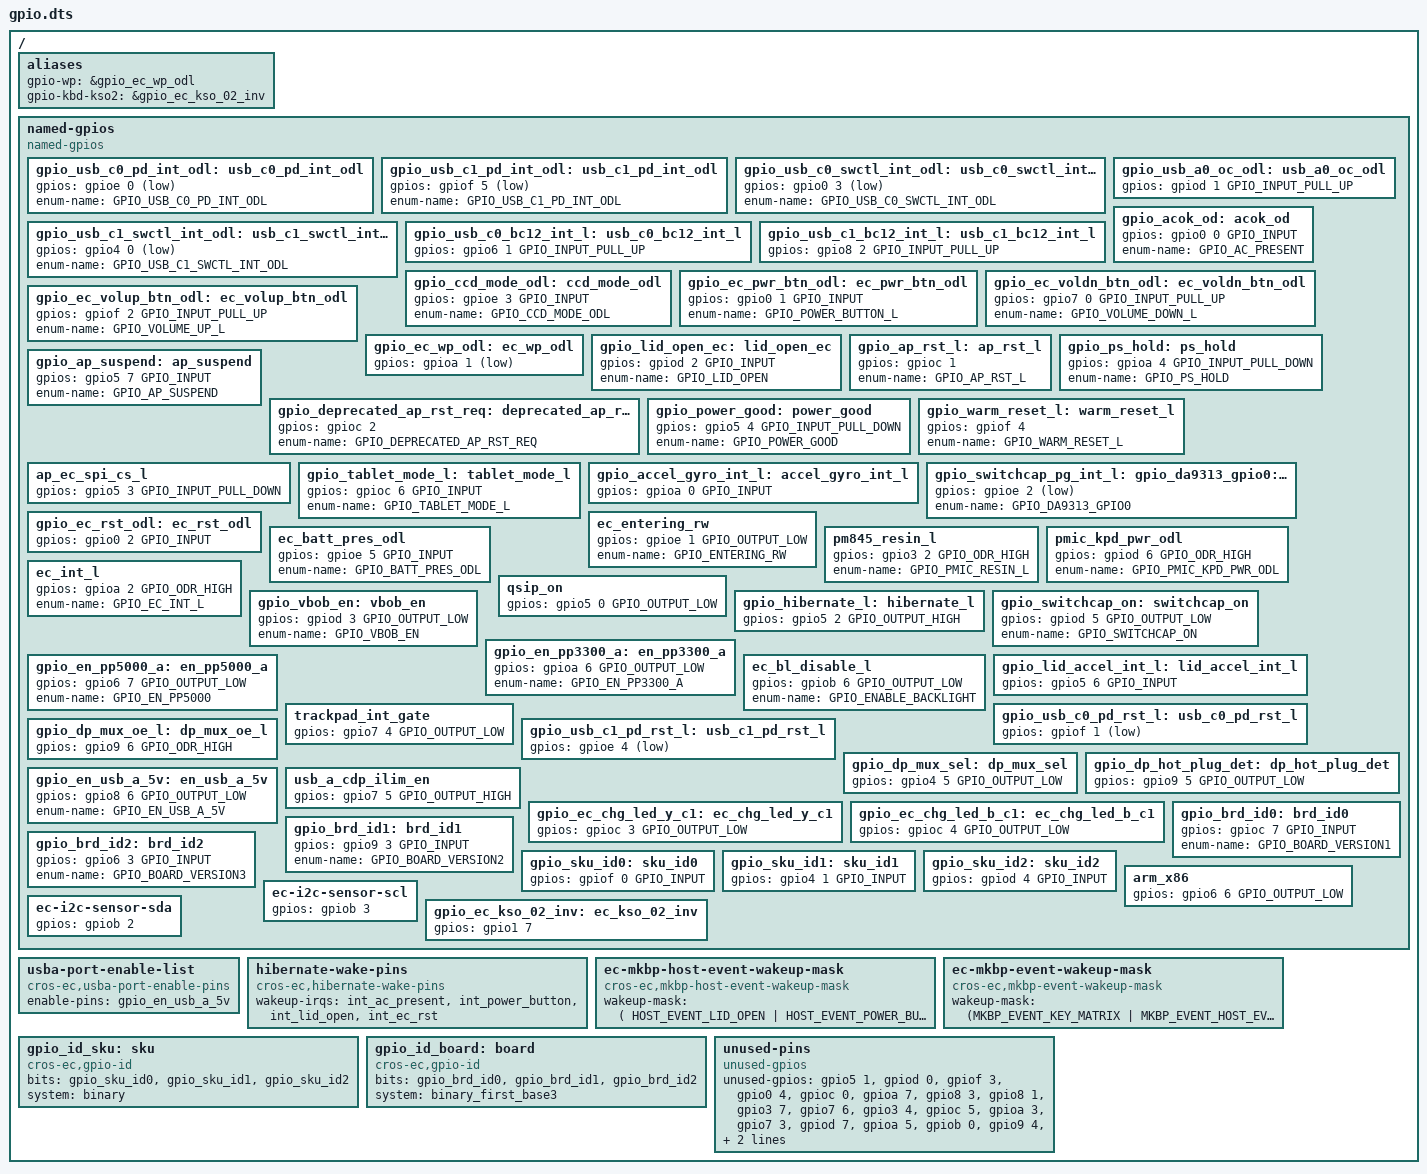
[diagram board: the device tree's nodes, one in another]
/* Copyright 2021 The ChromiumOS Authors
 * Use of this source code is governed by a BSD-style license that can be
 * found in the LICENSE file.
 */

#include <dt-bindings/wake_mask_event_defines.h>

/ {
	aliases {
		gpio-wp = &gpio_ec_wp_odl;
		gpio-kbd-kso2 = &gpio_ec_kso_02_inv;
	};

	named-gpios {
		compatible = "named-gpios";

		gpio_usb_c0_pd_int_odl: usb_c0_pd_int_odl {
			gpios = <&gpioe 0 (GPIO_INPUT | GPIO_ACTIVE_LOW)>;
			enum-name = "GPIO_USB_C0_PD_INT_ODL";
		};
		gpio_usb_c1_pd_int_odl: usb_c1_pd_int_odl {
			gpios = <&gpiof 5 (GPIO_INPUT | GPIO_ACTIVE_LOW)>;
			enum-name = "GPIO_USB_C1_PD_INT_ODL";
		};
		gpio_usb_c0_swctl_int_odl: usb_c0_swctl_int_odl {
			gpios = <&gpio0 3 (GPIO_INPUT | GPIO_ACTIVE_LOW)>;
			enum-name = "GPIO_USB_C0_SWCTL_INT_ODL";
		};
		gpio_usb_c1_swctl_int_odl: usb_c1_swctl_int_odl {
			gpios = <&gpio4 0 (GPIO_INPUT | GPIO_ACTIVE_LOW)>;
			enum-name = "GPIO_USB_C1_SWCTL_INT_ODL";
		};
		gpio_usb_c0_bc12_int_l: usb_c0_bc12_int_l {
			gpios = <&gpio6 1 GPIO_INPUT_PULL_UP>;
		};
		gpio_usb_c1_bc12_int_l: usb_c1_bc12_int_l {
			gpios = <&gpio8 2 GPIO_INPUT_PULL_UP>;
		};
		gpio_usb_a0_oc_odl: usb_a0_oc_odl {
			gpios = <&gpiod 1 GPIO_INPUT_PULL_UP>;
		};
		gpio_acok_od: acok_od {
			gpios = <&gpio0 0 GPIO_INPUT>;
			enum-name = "GPIO_AC_PRESENT";
		};
		gpio_ccd_mode_odl: ccd_mode_odl {
			gpios = <&gpioe 3 GPIO_INPUT>;
			enum-name = "GPIO_CCD_MODE_ODL";
		};
		gpio_ec_pwr_btn_odl: ec_pwr_btn_odl {
			gpios = <&gpio0 1 GPIO_INPUT>;
			enum-name = "GPIO_POWER_BUTTON_L";
		};
		gpio_ec_voldn_btn_odl: ec_voldn_btn_odl {
			gpios = <&gpio7 0 GPIO_INPUT_PULL_UP>;
			enum-name = "GPIO_VOLUME_DOWN_L";
		};
		gpio_ec_volup_btn_odl: ec_volup_btn_odl {
			gpios = <&gpiof 2 GPIO_INPUT_PULL_UP>;
			enum-name = "GPIO_VOLUME_UP_L";
		};
		gpio_ec_wp_odl: ec_wp_odl {
			gpios = <&gpioa 1 (GPIO_INPUT | GPIO_ACTIVE_LOW)>;
		};
		gpio_lid_open_ec: lid_open_ec {
			gpios = <&gpiod 2 GPIO_INPUT>;
			enum-name = "GPIO_LID_OPEN";
		};
		gpio_ap_rst_l: ap_rst_l {
			gpios = <&gpioc 1 (GPIO_INPUT | GPIO_VOLTAGE_1P8)>;
			enum-name = "GPIO_AP_RST_L";
		};
		gpio_ps_hold: ps_hold {
			gpios = <&gpioa 4 GPIO_INPUT_PULL_DOWN>;
			enum-name = "GPIO_PS_HOLD";
		};
		gpio_ap_suspend: ap_suspend {
			gpios = <&gpio5 7 GPIO_INPUT>;
			enum-name = "GPIO_AP_SUSPEND";
		};
		gpio_deprecated_ap_rst_req: deprecated_ap_rst_req {
			gpios = <&gpioc 2 (GPIO_INPUT_PULL_DOWN | GPIO_VOLTAGE_1P8)>;
			enum-name = "GPIO_DEPRECATED_AP_RST_REQ";
		};
		gpio_power_good: power_good {
			gpios = <&gpio5 4 GPIO_INPUT_PULL_DOWN>;
			enum-name = "GPIO_POWER_GOOD";
		};
		gpio_warm_reset_l: warm_reset_l {
			gpios = <&gpiof 4 (GPIO_INPUT | GPIO_VOLTAGE_1P8)>;
			enum-name = "GPIO_WARM_RESET_L";
		};
		ap_ec_spi_cs_l {
			gpios = <&gpio5 3 GPIO_INPUT_PULL_DOWN>;
		};
		gpio_tablet_mode_l: tablet_mode_l {
			gpios = <&gpioc 6 GPIO_INPUT>;
			enum-name = "GPIO_TABLET_MODE_L";
		};
		gpio_accel_gyro_int_l: accel_gyro_int_l {
			gpios = <&gpioa 0 GPIO_INPUT>;
		};
		/*
		 * Note, this signal is active low when used as the ln9310
		 * interrupt input, and active high when used as the da9313
		 * power good input.  The board code clears the active low
		 * flag when da9313 is detected.
		 */
		gpio_switchcap_pg_int_l: gpio_da9313_gpio0: da9313_gpio0 {
			gpios = <&gpioe 2 (GPIO_INPUT | GPIO_ACTIVE_LOW)>;
			enum-name = "GPIO_DA9313_GPIO0";
		};
		gpio_ec_rst_odl: ec_rst_odl {
			gpios = <&gpio0 2 GPIO_INPUT>;
		};
		ec_entering_rw {
			gpios = <&gpioe 1 GPIO_OUTPUT_LOW>;
			enum-name = "GPIO_ENTERING_RW";
		};
		ec_batt_pres_odl {
			gpios = <&gpioe 5 GPIO_INPUT>;
			enum-name = "GPIO_BATT_PRES_ODL";
		};
		pm845_resin_l {
			gpios = <&gpio3 2 GPIO_ODR_HIGH>;
			enum-name = "GPIO_PMIC_RESIN_L";
		};
		pmic_kpd_pwr_odl {
			gpios = <&gpiod 6 GPIO_ODR_HIGH>;
			enum-name = "GPIO_PMIC_KPD_PWR_ODL";
		};
		ec_int_l {
			gpios = <&gpioa 2 GPIO_ODR_HIGH>;
			enum-name = "GPIO_EC_INT_L";
		};
		qsip_on {
			gpios = <&gpio5 0 GPIO_OUTPUT_LOW>;
		};
		gpio_hibernate_l: hibernate_l {
			gpios = <&gpio5 2 GPIO_OUTPUT_HIGH>;
		};
		gpio_switchcap_on: switchcap_on {
			gpios = <&gpiod 5 GPIO_OUTPUT_LOW>;
			enum-name = "GPIO_SWITCHCAP_ON";
		};
		gpio_vbob_en: vbob_en {
			gpios = <&gpiod 3 GPIO_OUTPUT_LOW>;
			enum-name = "GPIO_VBOB_EN";
		};
		gpio_en_pp3300_a: en_pp3300_a {
			gpios = <&gpioa 6 GPIO_OUTPUT_LOW>;
			enum-name = "GPIO_EN_PP3300_A";
		};
		gpio_en_pp5000_a: en_pp5000_a {
			gpios = <&gpio6 7 GPIO_OUTPUT_LOW>;
			enum-name = "GPIO_EN_PP5000";
		};
		ec_bl_disable_l {
			gpios = <&gpiob 6 GPIO_OUTPUT_LOW>;
			enum-name = "GPIO_ENABLE_BACKLIGHT";
		};
		gpio_lid_accel_int_l: lid_accel_int_l {
			gpios = <&gpio5 6 GPIO_INPUT>;
		};
		trackpad_int_gate {
			gpios = <&gpio7 4 GPIO_OUTPUT_LOW>;
		};
		gpio_usb_c0_pd_rst_l: usb_c0_pd_rst_l {
			gpios = <&gpiof 1 (GPIO_ODR_HIGH | GPIO_ACTIVE_LOW)>;
		};
		gpio_usb_c1_pd_rst_l: usb_c1_pd_rst_l {
			gpios = <&gpioe 4 (GPIO_ODR_HIGH | GPIO_ACTIVE_LOW)>;
		};
		gpio_dp_mux_oe_l: dp_mux_oe_l {
			gpios = <&gpio9 6 GPIO_ODR_HIGH>;
		};
		gpio_dp_mux_sel: dp_mux_sel {
			gpios = <&gpio4 5 GPIO_OUTPUT_LOW>;
		};
		gpio_dp_hot_plug_det: dp_hot_plug_det {
			gpios = <&gpio9 5 GPIO_OUTPUT_LOW>;
		};
		gpio_en_usb_a_5v: en_usb_a_5v {
			gpios = <&gpio8 6 GPIO_OUTPUT_LOW>;
			enum-name = "GPIO_EN_USB_A_5V";
		};
		usb_a_cdp_ilim_en {
			gpios = <&gpio7 5 GPIO_OUTPUT_HIGH>;
		};
		gpio_ec_chg_led_y_c1: ec_chg_led_y_c1 {
			gpios = <&gpioc 3 GPIO_OUTPUT_LOW>;
		};
		gpio_ec_chg_led_b_c1: ec_chg_led_b_c1 {
			gpios = <&gpioc 4 GPIO_OUTPUT_LOW>;
		};
		gpio_brd_id0: brd_id0 {
			gpios = <&gpioc 7 GPIO_INPUT>;
			enum-name = "GPIO_BOARD_VERSION1";
		};
		gpio_brd_id1: brd_id1 {
			gpios = <&gpio9 3 GPIO_INPUT>;
			enum-name = "GPIO_BOARD_VERSION2";
		};
		gpio_brd_id2: brd_id2 {
			gpios = <&gpio6 3 GPIO_INPUT>;
			enum-name = "GPIO_BOARD_VERSION3";
		};
		gpio_sku_id0: sku_id0 {
			gpios = <&gpiof 0 GPIO_INPUT>;
		};
		gpio_sku_id1: sku_id1 {
			gpios = <&gpio4 1 GPIO_INPUT>;
		};
		gpio_sku_id2: sku_id2 {
			gpios = <&gpiod 4 GPIO_INPUT>;
		};
		arm_x86 {
			gpios = <&gpio6 6 GPIO_OUTPUT_LOW>;
		};
		ec-i2c-sensor-scl {
			gpios = <&gpiob 3 (GPIO_INPUT | GPIO_VOLTAGE_1P8)>;
		};
		ec-i2c-sensor-sda {
			gpios = <&gpiob 2 (GPIO_INPUT | GPIO_VOLTAGE_1P8)>;
		};
		gpio_ec_kso_02_inv: ec_kso_02_inv {
			gpios = <&gpio1 7 (GPIO_OUTPUT | GPIO_ACTIVE_HIGH)>;
		};
	};

	usba-port-enable-list {
		compatible = "cros-ec,usba-port-enable-pins";
		enable-pins = <&gpio_en_usb_a_5v>;
	};

	hibernate-wake-pins {
		compatible = "cros-ec,hibernate-wake-pins";
		wakeup-irqs = <
			&int_ac_present
			&int_power_button
			&int_lid_open
			&int_ec_rst
		>;
	};

	ec-mkbp-host-event-wakeup-mask {
		compatible = "cros-ec,mkbp-host-event-wakeup-mask";
		wakeup-mask = <(
			HOST_EVENT_LID_OPEN |
			HOST_EVENT_POWER_BUTTON |
			HOST_EVENT_AC_CONNECTED |
			HOST_EVENT_AC_DISCONNECTED |
			HOST_EVENT_HANG_DETECT |
			HOST_EVENT_RTC |
			HOST_EVENT_MODE_CHANGE |
			HOST_EVENT_DEVICE)>;
	};

	ec-mkbp-event-wakeup-mask {
		compatible = "cros-ec,mkbp-event-wakeup-mask";
		wakeup-mask = <(MKBP_EVENT_KEY_MATRIX |
				MKBP_EVENT_HOST_EVENT |
				MKBP_EVENT_SENSOR_FIFO)>;
	};

	gpio_id_sku: sku {
		compatible = "cros-ec,gpio-id";
		bits  = <
			&gpio_sku_id0
			&gpio_sku_id1
			&gpio_sku_id2
		>;
		system = "binary";
	};

	gpio_id_board: board {
		compatible = "cros-ec,gpio-id";
		bits  = <
			&gpio_brd_id0
			&gpio_brd_id1
			&gpio_brd_id2
		>;
		system = "binary_first_base3";
	};

	unused-pins {
		compatible = "unused-gpios";
		unused-gpios =
			<&gpio5 1 0>,
			<&gpiod 0 0>,
			<&gpiof 3 0>,
			<&gpio0 4 0>,
			<&gpioc 0 0>,
			<&gpioa 7 0>,
			<&gpio8 3 0>,
			<&gpio8 1 0>,
			<&gpio3 7 0>,
			<&gpio7 6 0>,
			<&gpio3 4 0>,
			<&gpioc 5 0>,
			<&gpioa 3 0>,
			<&gpio7 3 0>,
			<&gpiod 7 0>,
			<&gpioa 5 0>,
			<&gpiob 0 0>,
			<&gpio9 4 0>,
			<&gpiob 1 0>,
			<&gpio6 2 0>,
			<&gpio3 5 0>,
			<&gpio9 7 0>,
			<&gpio6 0 0>,
			<&gpio7 2 0>;
	};
};
